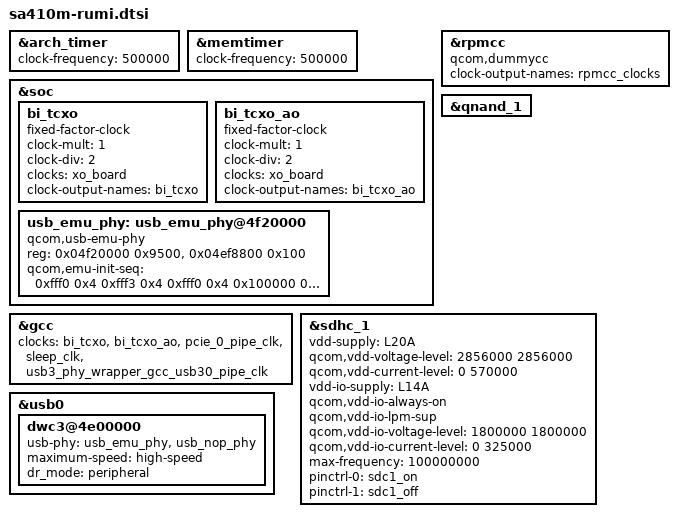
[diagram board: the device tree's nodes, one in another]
&arch_timer {
	clock-frequency = <500000>;
};

&memtimer {
	clock-frequency = <500000>;
};

&soc {
	bi_tcxo: bi_tcxo {
		compatible = "fixed-factor-clock";
		clock-mult = <1>;
		clock-div = <2>;
		clocks = <&xo_board>;
		clock-output-names = "bi_tcxo";
		#clock-cells = <0>;
	};

	bi_tcxo_ao: bi_tcxo_ao {
		compatible = "fixed-factor-clock";
		clock-mult = <1>;
		clock-div = <2>;
		clocks = <&xo_board>;
		clock-output-names = "bi_tcxo_ao";
		#clock-cells = <0>;
	};

	usb_emu_phy: usb_emu_phy@4f20000 {
			compatible = "qcom,usb-emu-phy";
			reg = <0x04f20000 0x9500>,
				<0x04ef8800 0x100>;
			reg-names = "base", "qscratch_base";

			qcom,emu-init-seq = <0xfff0 0x4
					     0xfff3 0x4
					     0xfff0 0x4
					     0x100000 0x20
					     0x0 0x20
					     0x101f0 0x20
					     0x100000 0x3c
					     0x0 0x3c
					     0x4 0x3c
					     0x0 0x4
					     0x9 0x14>;
	};
};

&rpmcc {
	compatible = "qcom,dummycc";
	clock-output-names = "rpmcc_clocks";
};

&gcc {
	clocks = <&bi_tcxo>, <&bi_tcxo_ao>, <&pcie_0_pipe_clk>,
		<&sleep_clk>, <&usb3_phy_wrapper_gcc_usb30_pipe_clk>;
};

&qnand_1 {
	status = "ok";
};

&sdhc_1 {
	status = "ok";
	vdd-supply = <&L20A>;
	qcom,vdd-voltage-level = <2856000 2856000>;
	qcom,vdd-current-level = <0 570000>;

	vdd-io-supply = <&L14A>;
	qcom,vdd-io-always-on;
	qcom,vdd-io-lpm-sup;
	qcom,vdd-io-voltage-level = <1800000 1800000>;
	qcom,vdd-io-current-level = <0 325000>;

	/delete-property/ mmc-ddr-1_8v;
	/delete-property/ mmc-hs200-1_8v;
	/delete-property/ mmc-hs400-1_8v;
	/delete-property/ mmc-hs400-enhanced-strobe;

	max-frequency = <100000000>;

	pinctrl-names = "default", "sleep";
	pinctrl-0 = <&sdc1_on>;
	pinctrl-1 = <&sdc1_off>;
};

&usb0 {
	dwc3@4e00000 {
		usb-phy = <&usb_emu_phy>, <&usb_nop_phy>;
		maximum-speed = "high-speed";
		dr_mode = "peripheral";
	};
};
